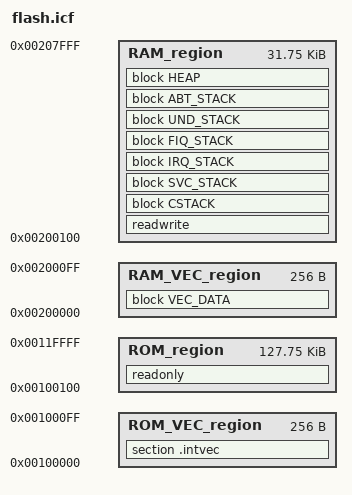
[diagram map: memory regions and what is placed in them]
/*###ICF### Section handled by ICF editor, don't touch! ****/
/*-Editor annotation file-*/
/* IcfEditorFile="$TOOLKIT_DIR$\config\ide\IcfEditor\a_v1_0.xml" */
/*-Specials-*/
define symbol __ICFEDIT_intvec_start__      = 0x00000000;

/*-Memory Regions-*/
define symbol __ICFEDIT_region_ROM_start__  = 0x00100000;
define symbol __ICFEDIT_region_ROM_end__    = 0x0011FFFF;
define symbol __ICFEDIT_region_RAM_start__  = 0x00200000;
define symbol __ICFEDIT_region_RAM_end__    = 0x00207FFF;

/*-Sizes-*/
define symbol __ICFEDIT_size_vectors__  = 0x100;

define symbol __ICFEDIT_size_cstack__   = 0x100;
define symbol __ICFEDIT_size_svcstack__ = 0x100;
define symbol __ICFEDIT_size_irqstack__ = 0x100;
define symbol __ICFEDIT_size_fiqstack__ = 0x10;
define symbol __ICFEDIT_size_undstack__ = 0x10;
define symbol __ICFEDIT_size_abtstack__ = 0x10;
define symbol __ICFEDIT_size_heap__     = 0x300;
/**** End of ICF editor section. ###ICF###*/


define memory mem with size = 4G;

define region ROM_VEC_region = mem:[from __ICFEDIT_region_ROM_start__ size __ICFEDIT_size_vectors__];
define region ROM_region = mem:[from __ICFEDIT_region_ROM_start__+__ICFEDIT_size_vectors__ to __ICFEDIT_region_ROM_end__];
define region RAM_VEC_region = mem:[from __ICFEDIT_region_RAM_start__ size __ICFEDIT_size_vectors__];
define region RAM_region = mem:[from __ICFEDIT_region_RAM_start__+__ICFEDIT_size_vectors__ to __ICFEDIT_region_RAM_end__];


define block VEC_DATA  with alignment = 8, size = __ICFEDIT_size_vectors__  { };
define block CSTACK    with alignment = 8, size = __ICFEDIT_size_cstack__   { };
define block SVC_STACK with alignment = 8, size = __ICFEDIT_size_svcstack__ { };
define block IRQ_STACK with alignment = 8, size = __ICFEDIT_size_irqstack__ { };
define block FIQ_STACK with alignment = 8, size = __ICFEDIT_size_fiqstack__ { };
define block UND_STACK with alignment = 8, size = __ICFEDIT_size_undstack__ { };
define block ABT_STACK with alignment = 8, size = __ICFEDIT_size_abtstack__ { };
define block HEAP      with alignment = 8, size = __ICFEDIT_size_heap__     { };

do not initialize  { section .noinit };
initialize by copy { readwrite };

place in ROM_VEC_region { section .intvec };
place in ROM_region     { readonly };

place in RAM_VEC_region { block VEC_DATA };
place in RAM_region     { readwrite,
                          block CSTACK, block SVC_STACK, block IRQ_STACK, block FIQ_STACK,
                          block UND_STACK, block ABT_STACK, block HEAP };
                        
                        
                        

